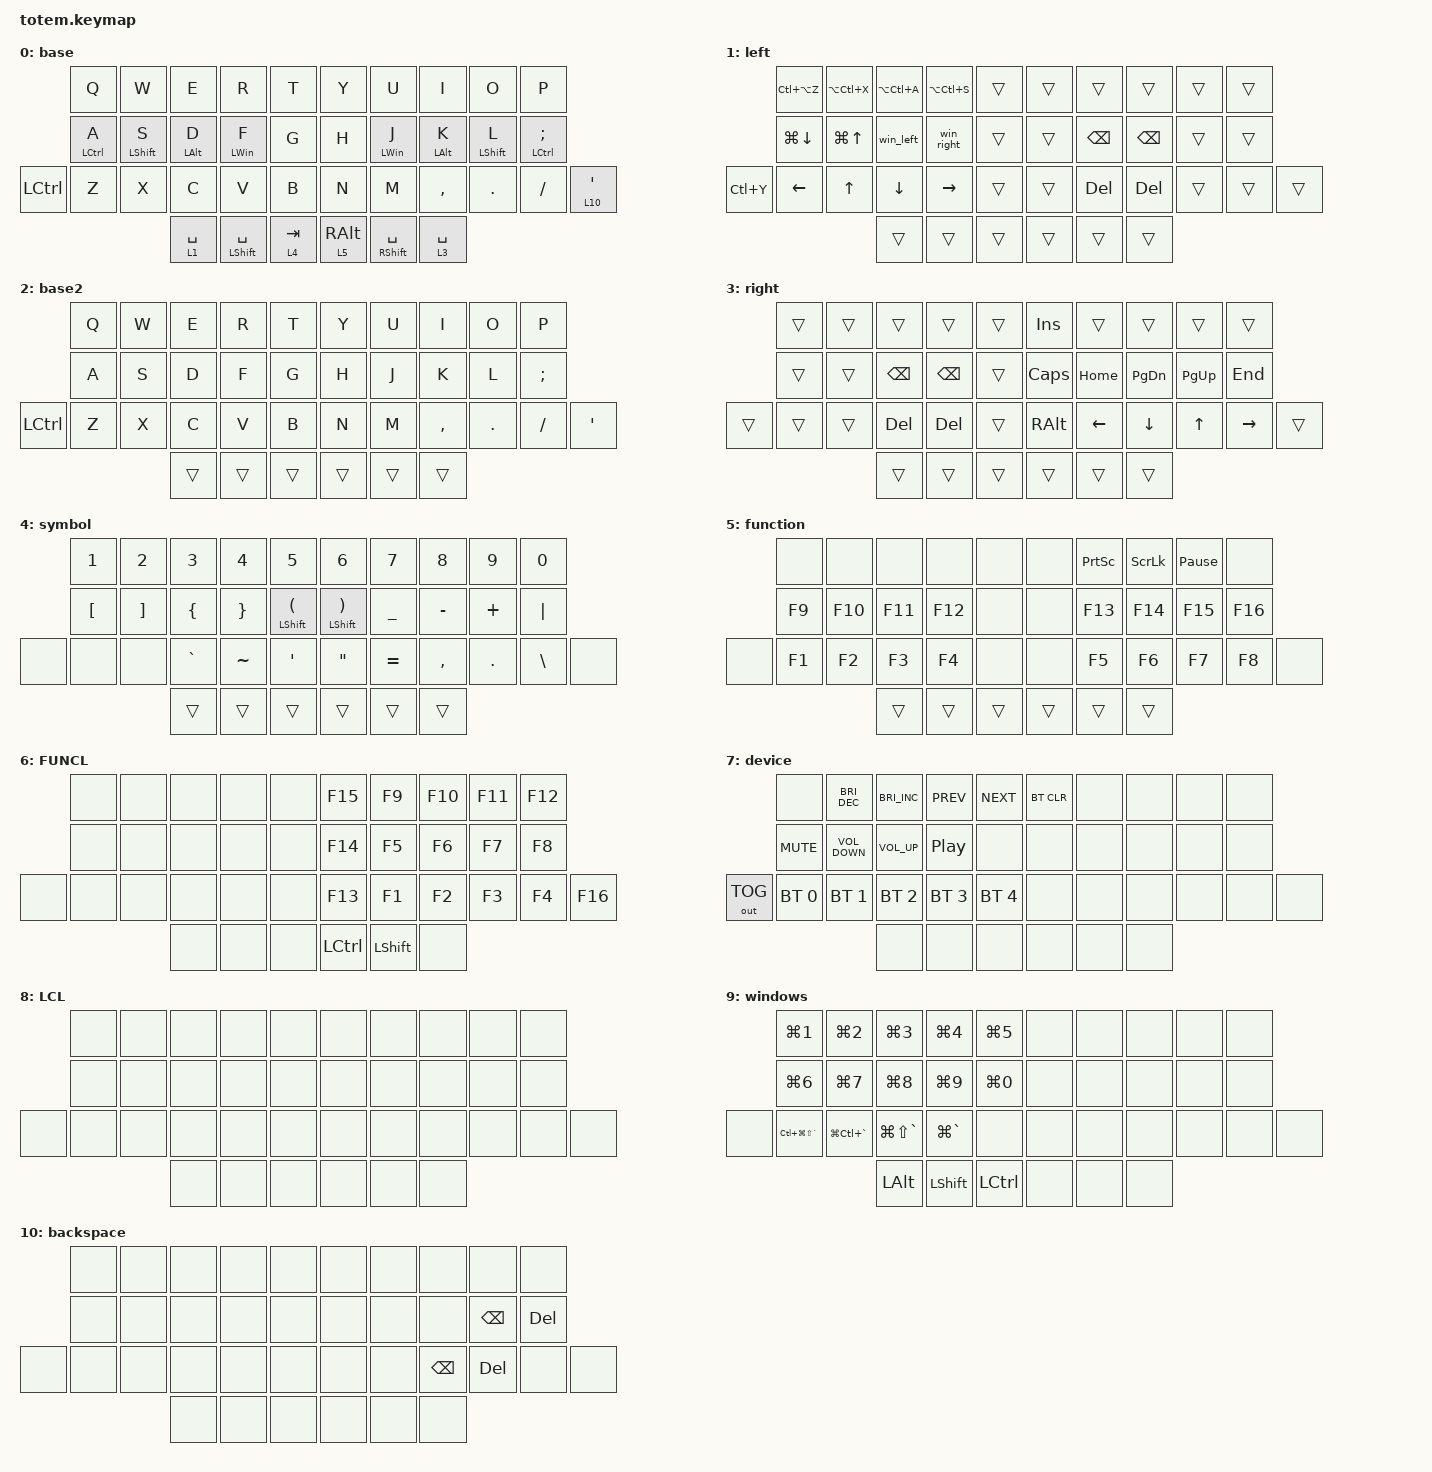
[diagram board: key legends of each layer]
//
//                                                        ▀▀▀▀▀     ▀▀▀▀▀          ▀▀█▀▀
//                                                        ▄▀▀▀▄  ▄  ▄▀▀▀▄  ▄  ▄▀▀▀▄  █  ▄▀▀▀▄
//                                                        █   █  █  █   █  █  █   █  █  █   █
//                                                         ▀▀▀   █   ▀▀▀   █   ▀▀▀   ▀   ▀▀▀
//                                                               █      ▄▄▄█▄▄▄    █   █  
//                                                               ▀      █  █  █     █▄█
//                                                             ▀▀▀▀▀    █  █  █      ▀
//                                                                      ▀  ▀  ▀
//
// ▄▄▄▄▄▄▄▄▄▄▄▄▄▄▄▄▄▄▄▄▄▄▄▄▄▄▄▄▄▄▄▄▄▄▄▄▄▄▄▄▄▄▄▄▄▄▄▄▄▄▄▄▄▄▄▄▄▄▄▄▄▄▄▄▄▄▄▄▄▄▄▄▄▄▄▄▄▄▄▄▄▄▄▄▄▄▄▄▄▄▄▄▄▄▄▄▄▄▄▄▄▄▄▄▄▄▄▄▄▄▄▄▄▄▄▄▄▄▄▄▄▄▄▄▄▄▄▄▄▄▄▄▄▄▄▄▄▄▄▄▄▄▄▄▄▄▄▄▄

#include <behaviors.dtsi>
#include <dt-bindings/zmk/bt.h>
#include <dt-bindings/zmk/keys.h>
#include <dt-bindings/zmk/outputs.h>
#include <dt-bindings/zmk/pointing.h>

&soft_off { hold-time-ms = <2000>; };

/ {
    quick_tab: quick_tab {
        compatible = "zmk,behavior-hold-tap";
        label = "QUICK_TAB";
        bindings = <&kp>, <&kp>;

        #binding-cells = <2>;
        tapping-term-ms = <250>;
        flavor = "tap-preferred";
        quick-tap-ms = <250>;
    };

    layer_quick_tab: layer_quick_tab {
        compatible = "zmk,behavior-hold-tap";
        label = "LAYER_QUICK_TAB";
        bindings = <&mo>, <&kp>;

        #binding-cells = <2>;
        tapping-term-ms = <150>;
        flavor = "balanced";
        retro-tap;
    };

    mouse_click_key: mouse_click_key {
        compatible = "zmk,behavior-hold-tap";
        label = "MOUSE_CLICK_KEY";
        bindings = <&mkp>, <&mkp>;

        #binding-cells = <2>;
        tapping-term-ms = <150>;
    };

    knob_mouse_scroll: knob_mouse_scroll {
        compatible = "zmk,behavior-sensor-rotate";
        label = "KNOB_MOUSE_SCROLL";
        #sensor-binding-cells = <0>;
        bindings = <&msc SCRL_DOWN>, <&msc SCRL_UP>;
    };

    mouse_click_tab_dance: mouse_click_tab_dance {
        compatible = "zmk,behavior-tap-dance";
        label = "MOUSE_CLICK_TAB_DANCE";
        #binding-cells = <0>;
        bindings = <&mkp LCLK>, <&mouse_click_key RCLK LCLK>;
    };

    layer_hold_tap: layer_hold_tap {
        compatible = "zmk,behavior-hold-tap";
        label = "LAYER_HOLD_TAP";
        bindings = <&mo>, <&tog>;

        #binding-cells = <2>;
        tapping-term-ms = <200>;
    };

    space_shift_homerow: space_shift_homerow {
        compatible = "zmk,behavior-hold-tap";
        label = "SPACE_SHIFT_HOMEROW";
        bindings = <&kp>, <&kp>;

        #binding-cells = <2>;
        flavor = "tap-preferred";
        tapping-term-ms = <150>;
        retro-tap;
    };

    quick_tab_retro: quick_tab_retro {
        compatible = "zmk,behavior-hold-tap";
        label = "QUICK_TAB_RETRO";
        bindings = <&kp>, <&kp>;

        #binding-cells = <2>;
        tapping-term-ms = <250>;
        flavor = "tap-preferred";
        quick-tap-ms = <150>;
        retro-tap;
    };

    combos {
        compatible = "zmk,combos";

        backspace_combo {
            bindings = <&kp BACKSPACE>;
            key-positions = <16 17>;
            layers = <0 4 5>;
            timeout-ms = <38>;
        };

        enter_combo {
            bindings = <&kp ENTER>;
            key-positions = <16 18>;
            layers = <0 4 5>;
            timeout-ms = <38>;
        };

        backspace2_combo {
            bindings = <&kp BACKSPACE>;
            key-positions = <13 12>;
            layers = <0 5 4>;
            timeout-ms = <38>;
        };

        enter2_combo {
            bindings = <&kp ENTER>;
            key-positions = <13 11>;
            layers = <0 5 4>;
            timeout-ms = <38>;
        };

        esc_combo {
            bindings = <&kp ESC>;
            key-positions = <2 1>;
            layers = <0 5>;
            timeout-ms = <38>;
        };

        delete_combo {
            bindings = <&kp DEL>;
            key-positions = <27 28>;
            timeout-ms = <38>;
            layers = <0 4 5>;
        };

        delete_combo2 {
            bindings = <&kp DEL>;
            key-positions = <24 23>;
            timeout-ms = <38>;
            layers = <0 5 4>;
        };

        win+e_combo {
            bindings = <&kp LG(E)>;
            key-positions = <2 1>;
            layers = <1>;
        };

        win+r_combo {
            bindings = <&kp LG(R)>;
            key-positions = <3 2>;
            layers = <1>;
        };

        win+shitf+t_combo {
            bindings = <&kp LG(LS(T))>;
            key-positions = <3 4>;
            layers = <1>;
        };

        win+shift+s_combo {
            bindings = <&kp LG(LS(S))>;
            key-positions = <10 11>;
            layers = <1>;
        };

        win+v_combo {
            bindings = <&kp LG(V)>;
            key-positions = <24 23>;
            layers = <1>;
        };

        device_layer_combo {
            bindings = <&mo 7>;
            key-positions = <35 36 37>;
        };

        switch_task_layer_combo {
            bindings = <&switch_tasks_layer>;
            key-positions = <35 37>;
        };
    };

    behaviors {
    };

    macros {
        win_left: win_left {
            compatible = "zmk,behavior-macro";
            label = "WIN_LEFT";
            #binding-cells = <0>;
            wait-ms = <0>;
            tap-ms = <0>;
            bindings =
                <&macro_press>,
                <&kp LGUI>,
                <&macro_tap>,
                <&kp LEFT>,
                <&macro_release>,
                <&kp LGUI>;
        };

        win_right: win_right {
            compatible = "zmk,behavior-macro";
            label = "WIN_RIGHT";
            #binding-cells = <0>;
            wait-ms = <0>;
            tap-ms = <0>;
            bindings =
                <&macro_press>,
                <&kp LGUI>,
                <&macro_tap>,
                <&kp RIGHT>,
                <&macro_release>,
                <&kp LGUI>;
        };

        switch_tasks_layer: switch_tasks_layer {
            compatible = "zmk,behavior-macro";
            #binding-cells = <0>;
            bindings =
                <&macro_press>,
                <&mo 9 &kp LEFT_GUI>,
                <&macro_pause_for_release>,
                <&macro_release>,
                <&mo 9 &kp LEFT_GUI>;

            label = "SWITCH_TASKS_LAYER";
        };
    };

    keymap {
        compatible = "zmk,keymap";

        BL {
            bindings = <
           &kp Q               &kp W                    &kp E                     &kp R                                  &kp T                     &kp Y                    &kp U                                   &kp I                     &kp O                    &kp P
           &quick_tab LCTRL A  &quick_tab LEFT_SHIFT S  &quick_tab LEFT_ALT D     &quick_tab_retro LEFT_WIN F            &kp G                     &kp H                    &quick_tab_retro LEFT_WIN J             &quick_tab LEFT_ALT K     &quick_tab LEFT_SHIFT L  &quick_tab LCTRL SEMI
&kp LCTRL  &kp Z               &kp X                    &kp C                     &kp V                                  &kp B                     &kp N                    &kp M                                   &kp COMMA                 &kp DOT                  &kp FSLH               &layer_quick_tab 10 APOS
                                                        &layer_quick_tab 1 SPACE  &space_shift_homerow LEFT_SHIFT SPACE  &layer_quick_tab 4 TAB    &layer_quick_tab 5 RALT  &space_shift_homerow RIGHT_SHIFT SPACE  &layer_quick_tab 3 SPACE
            >;

            label = "base";
        };

        LHL {
            bindings = <
           &kp LC(LA(Z))  &kp LA(LC(X))  &kp LA(LC(A))  &kp LA(LC(S))  &trans    &trans  &trans         &trans         &trans  &trans
           &kp LG(DOWN)   &kp LG(UP)     &win_left      &win_right     &trans    &trans  &kp BACKSPACE  &kp BACKSPACE  &trans  &trans
&kp LC(Y)  &kp LEFT       &kp UP         &kp DOWN       &kp RIGHT      &trans    &trans  &kp DEL        &kp DEL        &trans  &trans  &trans
                                         &trans         &trans         &trans    &trans  &trans         &trans
            >;

            label = "left";
        };

        DBL {
            bindings = <
           &kp Q  &kp W  &kp E   &kp R   &kp T     &kp Y   &kp U   &kp I      &kp O    &kp P
           &kp A  &kp S  &kp D   &kp F   &kp G     &kp H   &kp J   &kp K      &kp L    &kp SEMI
&kp LCTRL  &kp Z  &kp X  &kp C   &kp V   &kp B     &kp N   &kp M   &kp COMMA  &kp DOT  &kp FSLH  &kp APOS
                         &trans  &trans  &trans    &trans  &trans  &trans
            >;

            label = "base2";
        };

        RHL {
            bindings = <
        &trans  &trans  &trans         &trans         &trans    &kp INS   &trans    &trans     &trans     &trans
        &trans  &trans  &kp BACKSPACE  &kp BACKSPACE  &trans    &kp CAPS  &kp HOME  &kp PG_DN  &kp PG_UP  &kp END
&trans  &trans  &trans  &kp DEL        &kp DEL        &trans    &kp RALT  &kp LEFT  &kp DOWN   &kp UP     &kp RIGHT  &trans
                        &trans         &trans         &trans    &trans    &trans    &trans
            >;

            label = "right";
        };

        LTL {
            bindings = <
       &kp N1    &kp N2    &kp N3     &kp N4     &kp N5                        &kp N6                      &kp N7     &kp N8     &kp N9    &kp N0
       &kp LBKT  &kp RBKT  &kp LBRC   &kp RBRC   &quick_tab LEFT_SHIFT LPAR    &quick_tab LEFT_SHIFT RPAR  &kp UNDER  &kp MINUS  &kp PLUS  &kp PIPE
&none  &none     &none     &kp GRAVE  &kp TILDE  &kp APOS                      &kp DQT                     &kp EQUAL  &kp COMMA  &kp DOT   &kp BSLH  &none
                           &trans     &trans     &trans                        &trans                      &trans     &trans
            >;

            label = "symbol";
        };

        RTL {
            bindings = <
       &none   &none    &none    &none    &none     &none   &kp PSCRN  &kp SLCK  &kp PAUSE_BREAK  &none
       &kp F9  &kp F10  &kp F11  &kp F12  &none     &none   &kp F13    &kp F14   &kp F15          &kp F16
&none  &kp F1  &kp F2   &kp F3   &kp F4   &none     &none   &kp F5     &kp F6    &kp F7           &kp F8   &none
                        &trans   &trans   &trans    &trans  &trans     &trans
            >;

            label = "function";
        };

        FUNCL {
            bindings = <
       &none  &none  &none  &none  &none    &kp F15    &kp F9          &kp F10  &kp F11  &kp F12
       &none  &none  &none  &none  &none    &kp F14    &kp F5          &kp F6   &kp F7   &kp F8
&none  &none  &none  &none  &none  &none    &kp F13    &kp F1          &kp F2   &kp F3   &kp F4   &kp F16
                     &none  &none  &none    &kp LCTRL  &kp LEFT_SHIFT  &none
            >;
        };

        DEVL {
            bindings = <
              &none         &kp C_BRIGHTNESS_DEC  &kp C_BRIGHTNESS_INC  &kp C_PREV        &kp C_NEXT      &bt BT_CLR  &none  &none  &none  &none
              &kp C_MUTE    &kp C_VOLUME_DOWN     &kp C_VOLUME_UP       &kp C_PLAY_PAUSE  &none           &none       &none  &none  &none  &none
&out OUT_TOG  &bt BT_SEL 0  &bt BT_SEL 1          &bt BT_SEL 2          &bt BT_SEL 3      &bt BT_SEL 4    &none       &none  &none  &none  &none  &none
                                                  &none                 &none             &none           &none       &none  &none
            >;

            label = "device";
        };

        LCL {
            bindings = <
       &none  &none  &none  &none  &none    &none  &none  &none  &none  &none
       &none  &none  &none  &none  &none    &none  &none  &none  &none  &none
&none  &none  &none  &none  &none  &none    &none  &none  &none  &none  &none  &none
                     &none  &none  &none    &none  &none  &none
            >;
        };

        RCL {
            bindings = <
       &kp LG(N1)             &kp LG(N2)         &kp LG(N3)         &kp LG(N4)     &kp LG(N5)    &none  &none  &none  &none  &none
       &kp LG(N6)             &kp LG(N7)         &kp LG(N8)         &kp LG(N9)     &kp LG(N0)    &none  &none  &none  &none  &none
&none  &kp LC(LG(LS(GRAVE)))  &kp LG(LC(GRAVE))  &kp LG(LS(GRAVE))  &kp LG(GRAVE)  &none         &none  &none  &none  &none  &none  &none
                                                 &kp LEFT_ALT       &kp LSHIFT     &kp LCTRL     &none  &none  &none
            >;

            label = "windows";
        };

        BSL {
            bindings = <
       &none  &none  &none  &none  &none    &none  &none  &none          &none          &none
       &none  &none  &none  &none  &none    &none  &none  &none          &kp BACKSPACE  &kp DEL
&none  &none  &none  &none  &none  &none    &none  &none  &kp BACKSPACE  &kp DEL        &none    &none
                     &none  &none  &none    &none  &none  &none
            >;

            label = "backspace";
        };
    };

    conditional_layers { compatible = "zmk,conditional-layers"; };
};
